AUTOSAR XML (schema 4-3-0)
package /cdd_wpcic
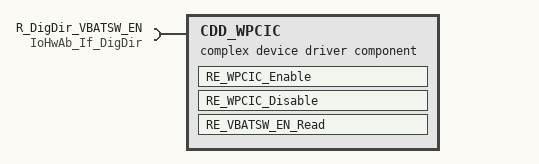
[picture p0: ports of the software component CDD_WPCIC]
  complex device driver sw component type CDD_WPCIC
    require port R_DigDir_VBATSW_EN: required-com-specs=[WriteDirect, ReadDirect], required-interface=IoHwAb_If_DigDir
    behavior InternalBehavior
      runnable RE_WPCIC_Enable: symbol=wpcic_enable
        sync call SSCP_RE_WPCIC_Enable_R_DigDir_VBATSW_EN_WriteDirect: operation=R_DigDir_VBATSW_EN.WriteDirect
      runnable RE_WPCIC_Disable: symbol=wpcic_disable
        sync call SSCP_RE_WPCIC_Disable_R_DigDir_VBATSW_EN_WriteDirect: operation=R_DigDir_VBATSW_EN.WriteDirect, timeout=0.0
      runnable RE_VBATSW_EN_Read: symbol=VBATSW_EN_Read
        sync call SSCP_RE_VBATSW_EN_Read_R_DigDir_VBATSW_EN_ReadDirect: operation=R_DigDir_VBATSW_EN.ReadDirect
